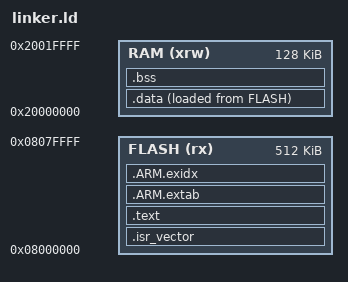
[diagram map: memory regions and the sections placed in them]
/* STM32F411RE linker script */

ENTRY(Reset_Handler)

/* Memory layout */
MEMORY
{
    FLASH (rx)  : ORIGIN = 0x08000000, LENGTH = 512K
    RAM   (xrw) : ORIGIN = 0x20000000, LENGTH = 128K
}

/* Initial stack pointer: top of SRAM */
_estack = ORIGIN(RAM) + LENGTH(RAM);

SECTIONS
{
    /* Interrupt vector table must be first in Flash */
    .isr_vector :
    {
        . = ALIGN(4);
        KEEP(*(.isr_vector))
        . = ALIGN(4);
    } > FLASH

    /* Program code and read-only data */
    .text :
    {
        . = ALIGN(4);
        *(.text.Reset_Handler)
        *(.text*)
        *(.rodata*)
        *(.glue_7)
        *(.glue_7t)
        KEEP(*(.init))
        KEEP(*(.fini))
        . = ALIGN(4);
    } > FLASH

    /* ARM exception-index sections */
    .ARM.extab :
    {
        *(.ARM.extab*)
    } > FLASH

    .ARM.exidx :
    {
        __exidx_start = .;
        *(.ARM.exidx*)
        __exidx_end = .;
    } > FLASH

    /* Initialized variables: stored in Flash, copied to RAM */
    _sidata = LOADADDR(.data);

    .data :
    {
        . = ALIGN(4);
        _sdata = .;
        *(.data*)
        . = ALIGN(4);
        _edata = .;
    } > RAM AT > FLASH

    /* Zero-initialized variables */
    .bss (NOLOAD) :
    {
        . = ALIGN(4);
        _sbss = .;
        *(.bss*)
        *(COMMON)
        . = ALIGN(4);
        _ebss = .;
    } > RAM

    /* End of statically allocated RAM */
    . = ALIGN(8);
    _end = .;
    PROVIDE(end = .);

    /* Keep compiler metadata out of the loadable image */
    /DISCARD/ :
    {
        *(.note*)
    }
}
